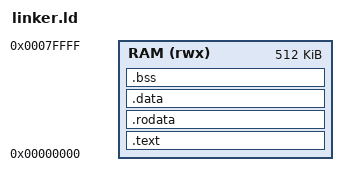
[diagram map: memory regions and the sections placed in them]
ENTRY(_start)

MEMORY
{
    RAM (rwx) : ORIGIN = 0x00000000, LENGTH = 512K
}

SECTIONS
{
    .text :
    {
        KEEP(*(.vectors))
        *(.text*)
    } > RAM

    .rodata :
    {
        *(.rodata*)
    } > RAM

    .data :
    {
        *(.data*)
    } > RAM

    .bss :
    {
        *(.bss*)
        *(COMMON)
    } > RAM

    . = ALIGN(8);
    _stack_top = . + 0x4000;
}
